# GD32C221 register map
File version: 1.0
CPU: CM23 r0p0, little endian, MPU, FPU, 4 interrupt priority bits
Registers are 32-bit, read-write, reset 0x0 unless marked. A register's access mark holds for its fields unless they carry their own. Offsets are from the block's base; [hi:lo] are bit positions.

## RCU — Reset and clock unit
Base 0x40021000
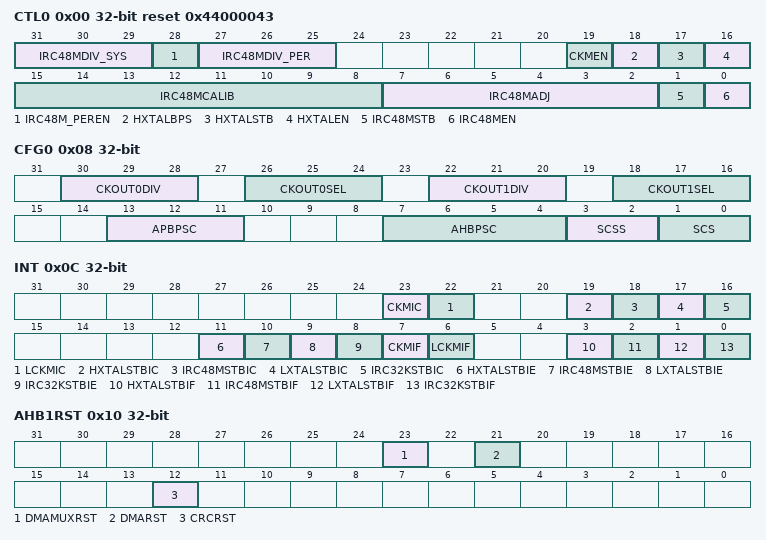
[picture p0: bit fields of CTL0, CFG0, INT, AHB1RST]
0x00 CTL0 access per field reset 0x44000043 — Control register 0
  [31:29] IRC48MDIV_SYS rw — IRC48M clock divider factor for system clock
  [28] IRC48M_PEREN rw — IRC48M always-enable for peripheral.
  [27:25] IRC48MDIV_PER rw — IRC48M clock divider factor for peripheral clock
  [19] CKMEN rw — HXTAL clock monitor enable
  [18] HXTALBPS rw — External crystal oscillator (HXTAL) clock bypass mode enable
  [17] HXTALSTB ro — External crystal oscillator (HXTAL) clock stabilization flag
  [16] HXTALEN rw — External high speed oscillator enable
  [15:8] IRC48MCALIB ro — Internal 48M RC oscillator calibration value register
  [7:2] IRC48MADJ rw — Internal 48M RC oscillator clock trim adjust value
  [1] IRC48MSTB ro — IRC48M high speed internal oscillator stabilization flag
  [0] IRC48MEN rw — Internal high speed oscillator enable
0x08 CFG0 access per field — Configuration register 0
  [30:28] CKOUT0DIV rw — The CK_OUT0 divider which the CK_OUT0 frequency can be reduced,
  [26:24] CKOUT0SEL rw — CK_OUT0 clock source selection
  [22:20] CKOUT1DIV rw — The CK_OUT1 divider which the CK_OUT1 frequency can be reduced,
  [18:16] CKOUT1SEL rw — CK_OUT1 clock source selection
  [13:11] APBPSC rw — APB prescaler selection
  [7:4] AHBPSC rw — AHB prescaler selection
  [3:2] SCSS ro — System clock switch status
  [1:0] SCS rw — System clock switch
0x0C INT access per field — Interrupt register
  [23] CKMIC wo — HXTAL clock stuck interrupt clear
  [22] LCKMIC wo — LXTAL clock stuck interrupt clear
  [19] HXTALSTBIC wo — HXTAL stabilization interrupt clear
  [18] IRC48MSTBIC wo — IRC48M stabilization interrupt clear
  [17] LXTALSTBIC wo — LXTAL stabilization interrupt clear
  [16] IRC32KSTBIC wo — IRC32K stabilization interrupt clear
  [11] HXTALSTBIE rw — HXTAL stabilization interrupt enable
  [10] IRC48MSTBIE rw — IRC48M stabilization interrupt enable
  [9] LXTALSTBIE rw — LXTAL stabilization interrupt enable
  [8] IRC32KSTBIE rw — IRC32K stabilization interrupt enable
  [7] CKMIF ro — HXTAL clock stuck interrupt flag
  [6] LCKMIF ro — LXTAL clock stuck interrupt flag
  [3] HXTALSTBIF ro — HXTAL stabilization interrupt flag
  [2] IRC48MSTBIF ro — IRC48M stabilization interrupt flag
  [1] LXTALSTBIF ro — LXTAL stabilization interrupt flag
  [0] IRC32KSTBIF ro — IRC32K stabilization interrupt flag
0x10 AHB1RST — AHB1 reset register
  [23] DMAMUXRST — DMAMUX reset
  [21] DMARST — DMA reset
  [12] CRCRST — CRC Reset
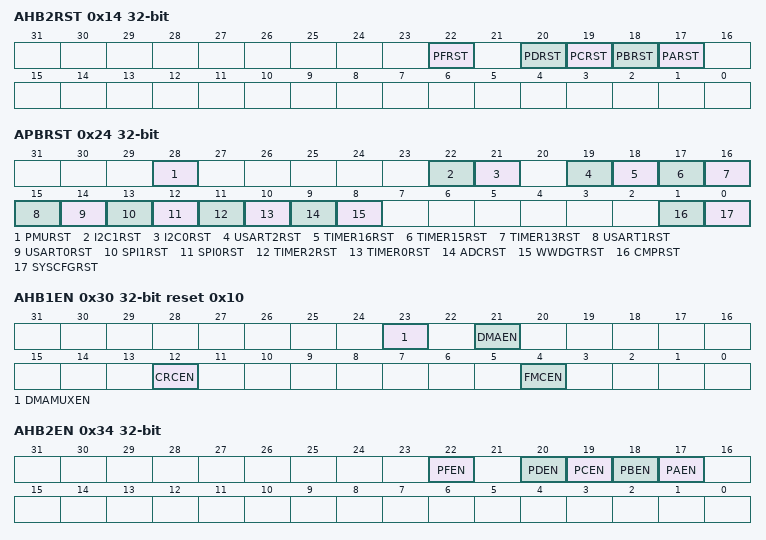
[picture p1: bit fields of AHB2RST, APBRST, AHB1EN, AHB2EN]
0x14 AHB2RST — AHB2 reset register
  [22] PFRST — GPIO port F reset
  [20] PDRST — GPIO port D reset
  [19] PCRST — GPIO port C reset
  [18] PBRST — GPIO port B reset
  [17] PARST — GPIO port A reset
0x24 APBRST — APB reset register
  [28] PMURST — PMU reset
  [22] I2C1RST — I2C1 reset
  [21] I2C0RST — I2C0 reset
  [19] USART2RST — USART2 Reset
  [18] TIMER16RST — TIMER16 reset
  [17] TIMER15RST — TIMER15 reset
  [16] TIMER13RST — TIMER13 reset
  [15] USART1RST — USART1 Reset
  [14] USART0RST — USART0 Reset
  [13] SPI1RST — SPI1 Reset
  [12] SPI0RST — SPI0 Reset
  [11] TIMER2RST — TIMER2 reset
  [10] TIMER0RST — TIMER0 reset
  [9] ADCRST — ADC reset
  [8] WWDGTRST — WWDGT reset
  [1] CMPRST — Comparator reset
  [0] SYSCFGRST — System configuration reset
0x30 AHB1EN reset 0x10 — AHB1 enable register
  [23] DMAMUXEN — DMAMUX clock enable
  [21] DMAEN — DMA clock enable
  [12] CRCEN — CRC clock enable
  [4] FMCEN — FMC clock enable
0x34 AHB2EN — AHB2 enable register
  [22] PFEN — GPIO port F clock enable
  [20] PDEN — GPIO port D clock enable
  [19] PCEN — GPIO port C clock enable
  [18] PBEN — GPIO port B clock enable
  [17] PAEN — GPIO port A clock enable
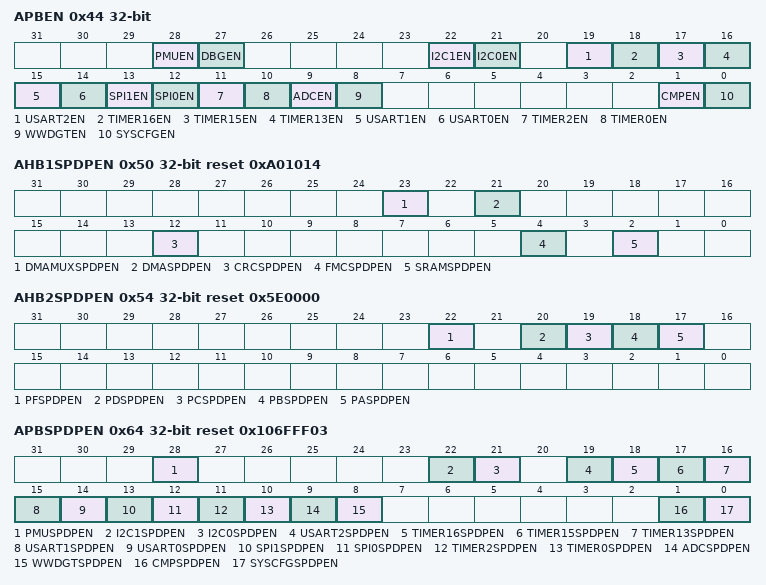
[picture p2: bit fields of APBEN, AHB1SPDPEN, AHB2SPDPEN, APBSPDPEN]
0x44 APBEN — APB enable register
  [28] PMUEN — PMU clock enable
  [27] DBGEN — DBG clock enable
  [22] I2C1EN — I2C1 clock enable
  [21] I2C0EN — I2C0 clock enable
  [19] USART2EN — USART2 clock enable
  [18] TIMER16EN — TIMER16 timer clock enable
  [17] TIMER15EN — TIMER15 timer clock enable
  [16] TIMER13EN — TIMER13 timer clock enable
  [15] USART1EN — USART1 clock enable
  [14] USART0EN — USART0 clock enable
  [13] SPI1EN — SPI1 clock enable
  [12] SPI0EN — SPI0 clock enable
  [11] TIMER2EN — TIMER2 timer clock enable
  [10] TIMER0EN — TIMER0 timer clock enable
  [9] ADCEN — ADC interface clock enable
  [8] WWDGTEN — WWDGT clock enable
  [1] CMPEN — Comparator clock enable
  [0] SYSCFGEN — System configuration clock enable
0x50 AHB1SPDPEN reset 0xA01014 — AHB1 sleep and deep sleep mode enable register
  [23] DMAMUXSPDPEN — DMAMUX clock enable when sleep and deep sleep mode
  [21] DMASPDPEN — DMA clock enable when sleep and deep sleep mode
  [12] CRCSPDPEN — CRC clock enable when sleep and deep sleep mode
  [4] FMCSPDPEN — FMC clock enable when sleep and deep sleep mode
  [2] SRAMSPDPEN — SRAM interface clock enable when sleep and deep sleep mode
0x54 AHB2SPDPEN reset 0x5E0000 — AHB2 sleep and deep sleep mode enable register
  [22] PFSPDPEN — GPIO port F clock enable when sleep and deep sleep mode
  [20] PDSPDPEN — GPIO port D clock enable when sleep and deep sleep mode
  [19] PCSPDPEN — GPIO port C clock enable when sleep and deep sleep mode
  [18] PBSPDPEN — GPIO port B clock enable when sleep and deep sleep mode
  [17] PASPDPEN — GPIO port A clock enable when sleep and deep sleep mode
0x64 APBSPDPEN reset 0x106FFF03 — APB sleep and deep sleep mode enable register
  [28] PMUSPDPEN — PMU clock enable when sleep and deep sleep mode
  [22] I2C1SPDPEN — I2C1 clock enable when sleep mode and deep sleep mode
  [21] I2C0SPDPEN — I2C0 clock enable when sleep mode and deep sleep mode
  [19] USART2SPDPEN — USART2 clock enable when sleep mode and deep sleep mode
  [18] TIMER16SPDPEN — TIMER16 clock enable when sleep and deep sleep mode
  [17] TIMER15SPDPEN — TIMER15 clock enable when sleep and deep sleep mode
  [16] TIMER13SPDPEN — TIMER13 clock enable when sleep and deep sleep mode
  [15] USART1SPDPEN — USART1 clock enable when sleep and deep sleep mode
  [14] USART0SPDPEN — USART0 clock enable when sleep and deep sleep mode
  [13] SPI1SPDPEN — SPI1 clock enable when sleep and deep sleep mode
  [12] SPI0SPDPEN — SPI0 clock enable when sleep and deep sleep mode
  [11] TIMER2SPDPEN — TIMER2 clock enable when sleep and deep sleep mode
  [10] TIMER0SPDPEN — TIMER0 clock enable when sleep and deep sleep mode
  [9] ADCSPDPEN — ADC clock enable when sleep and deep sleep mode
  [8] WWDGTSPDPEN — WWDGT clock enable when sleep and deep sleep mode
  [1] CMPSPDPEN — CMP clock enable when sleep and deep sleep mode
  [0] SYSCFGSPDPEN — System configuration clock enable when sleep and deep sleep mode
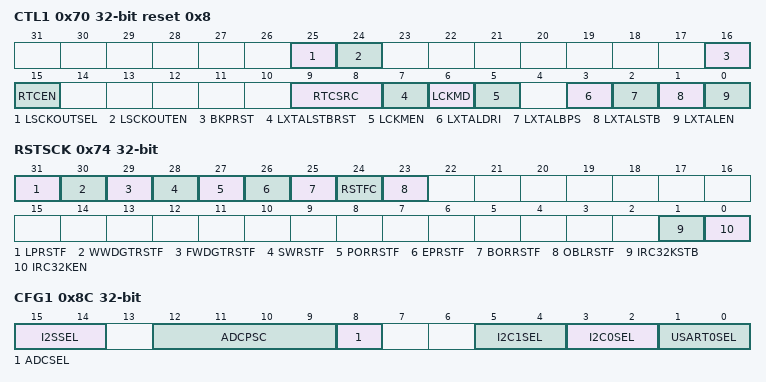
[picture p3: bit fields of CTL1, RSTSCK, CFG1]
0x70 CTL1 access per field reset 0x8 — Control register 1
  [25] LSCKOUTSEL rw — Low speed clock output selection
  [24] LSCKOUTEN rw — Low speed clock output enable
  [16] BKPRST rw — Backup register reset
  [15] RTCEN rw — RTC clock enable
  [9:8] RTCSRC rw — RTC clock entry selection
  [7] LXTALSTBRST rw — LXTAL stabilization reset.
  [6] LCKMD rw — LXTAL clock failure detection
  [5] LCKMEN rw — LXTAL clock monitor enable
  [3] LXTALDRI rw — LXTAL drive capability
  [2] LXTALBPS rw — LXTAL bypass mode enable
  [1] LXTALSTB ro — External low-speed oscillator stabilization
  [0] LXTALEN rw — LXTAL enable
0x74 RSTSCK access per field — Reset source /clock register
  [31] LPRSTF ro — Low-power reset flag
  [30] WWDGTRSTF ro — Window watchdog timer reset flag
  [29] FWDGTRSTF ro — Free Watchdog timer reset flag
  [28] SWRSTF ro — Software reset flag
  [27] PORRSTF ro — Power reset flag
  [26] EPRSTF ro — External PIN reset flag
  [25] BORRSTF ro — BOR reset flag
  [24] RSTFC rw — Reset flag clear
  [23] OBLRSTF ro — Option byte loader reset flag
  [1] IRC32KSTB ro — IRC32K stabilization
  [0] IRC32KEN rw — IRC32K enable
0x8C CFG1 — Configuration register 1
  [15:14] I2SSEL — I2S clock source selection
  [12:9] ADCPSC — ADC clock prescaler selection
  [8] ADCSEL — CK_ADC clock source selection
  [5:4] I2C1SEL — CK_I2C1 clock source selection
  [3:2] I2C0SEL — CK_I2C0 clock source selection
  [1:0] USART0SEL — CK_USART0 clock source selection
